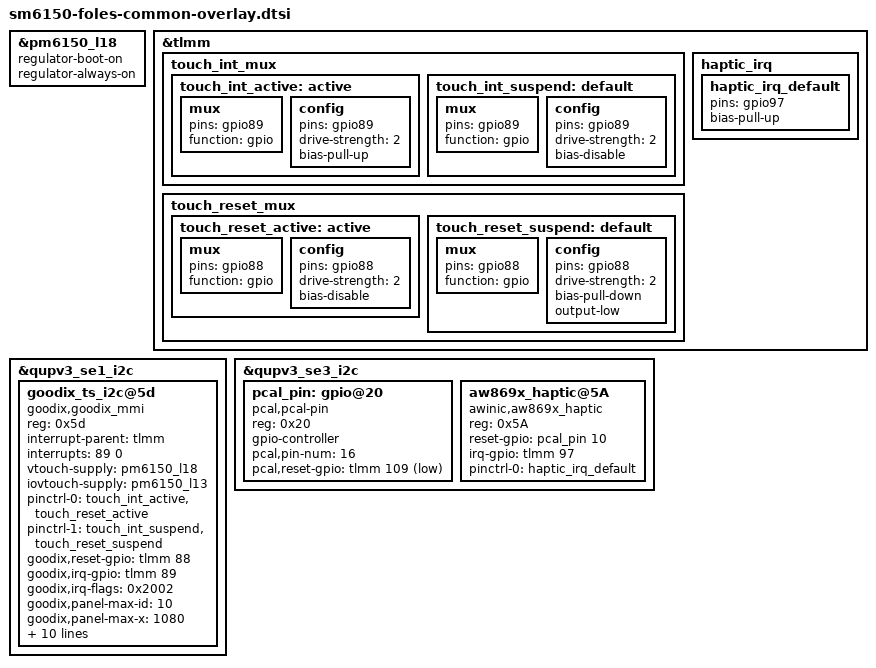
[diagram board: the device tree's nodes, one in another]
/* Copyright (c) 2018, The Linux Foundation. All rights reserved.
 *
 * This program is free software; you can redistribute it and/or modify
 * it under the terms of the GNU General Public License version 2 and
 * only version 2 as published by the Free Software Foundation.
 *
 * This program is distributed in the hope that it will be useful,
 * but WITHOUT ANY WARRANTY; without even the implied warranty of
 * MERCHANTABILITY or FITNESS FOR A PARTICULAR PURPOSE.  See the
 * GNU General Public License for more details.
 */

#include "sm6150-moto-common-overlay.dtsi"
#include "sm6150-audio-overlay.dtsi"


&pm6150_l18 {
	regulator-boot-on;
	regulator-always-on;

	status = "ok";
};

&tlmm {
	touch_int_mux {
		touch_int_active: active {
			mux {
				pins = "gpio89";
				function = "gpio";
			};
			config {
				pins = "gpio89";
				drive-strength = <2>;
				bias-pull-up;
			};
		};

		touch_int_suspend: default {
			mux {
				pins = "gpio89";
				function = "gpio";
			};
			config {
				pins = "gpio89";
				drive-strength = <2>;
				bias-disable;
			};
		};
	};

	touch_reset_mux {
		touch_reset_active: active {
			mux {
				pins = "gpio88";
				function = "gpio";
			};
			config {
				pins = "gpio88";
				drive-strength = <2>;
				bias-disable;
			};
		};

		touch_reset_suspend: default {
			mux {
				pins = "gpio88";
				function = "gpio";
			};
			config {
				pins = "gpio88";
				drive-strength = <2>;
				bias-pull-down;
				output-low;
			};
		};
	};
};

&tlmm{
	haptic_irq {
		haptic_irq_default: haptic_irq_default {
			pins = "gpio97";
			bias-pull-up;
		};
	};
};

&qupv3_se1_i2c {
	status = "okay";

	goodix_ts_i2c@5d {
		compatible = "goodix,goodix_mmi";
		reg = <0x5d>;
		status = "ok";
		interrupt-parent = <&tlmm>;
		interrupts = <89 0>;
		vtouch-supply = <&pm6150_l18>;
		iovtouch-supply = <&pm6150_l13>;
		//vtouch-supply = <&tlmm 88 0>;
		pinctrl-names = "pmx_ts_active","pmx_ts_suspend";
		pinctrl-0 = <&touch_int_active &touch_reset_active>;
		pinctrl-1 = <&touch_int_suspend &touch_reset_suspend>;
		goodix,reset-gpio = <&tlmm 88 0x0>;
		goodix,irq-gpio = <&tlmm 89 0x2002>;
		goodix,irq-flags = <0x2002>; /* 1:trigger rising, 2:trigger falling;*/
		goodix,panel-max-id = <10>;
		goodix,panel-max-x = <1080>;
		goodix,panel-max-y = <2340>;
		goodix,panel-max-w = <512>;
		goodix,panel-max-p = <512>;
		goodix,panel-key-map = <158 172 217>; /*KEY_BACK, KEY_HOMEPAGE, KEY_SEARCH*/
		goodix,power-on-delay-us = <300000>; /*300ms*/
		goodix,power-off-delay-us = <5000>;
		/*goodix,swap-axis;*/
		goodix,x2x;
		goodix,y2y;
		goodix,pen-enable;
		goodix,key-of-pen = <331 332>;/*BTN_STYLUS, BTN_STYLUS2*/
	};
};

&qupv3_se3_i2c {
	status = "okay";

	pcal_pin:gpio@20 {
		compatible = "pcal,pcal-pin";
		status = "ok";
		reg = <0x20>;
		gpio-controller;
		#gpio-cells = <2>;
		#address-cells = <1>;
		pcal,pin-num = <16>;
		pcal,reset-gpio = <&tlmm 109 1>;
	};

	aw869x_haptic@5A {
		compatible = "awinic,aw869x_haptic";
		reg = <0x5A>;
		reset-gpio = <&pcal_pin 10 0>;
		irq-gpio = <&tlmm 97 0>;
		pinctrl-names = "default";
		pinctrl-0 = <&haptic_irq_default>;
		status = "okay";
	};
};
